# IVA_PRM register map
Vendor: Texas Instruments
Peripheral module from a debugger description file (folder omap5430_ES2_PUBLIC).
Registers are 32-bit, access not given, reset 0xFF0E03 unless marked. A register's access mark holds for its fields unless they carry their own. Offsets are as the file gives them; lines under a group give offsets from that group; [hi:lo] are bit positions; {n}, {i} and the like mark numbered series; 'fields as' and 'values as' point back to an identical list; <NAME> marks a mode.

## IVA_PRM
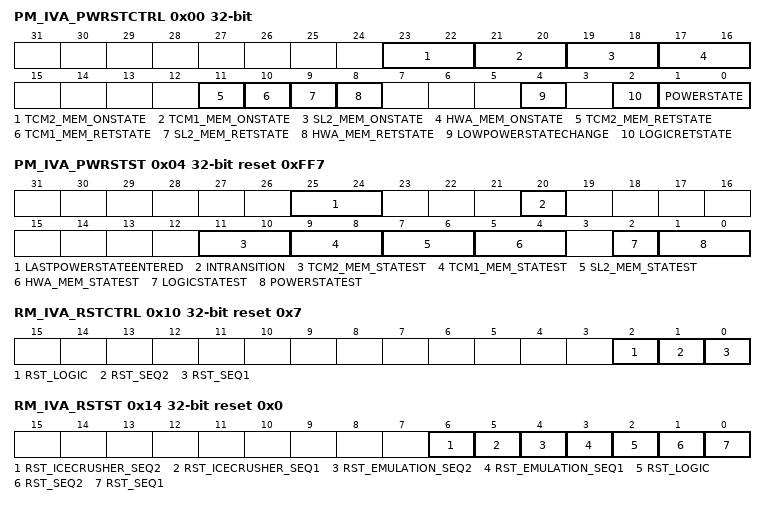
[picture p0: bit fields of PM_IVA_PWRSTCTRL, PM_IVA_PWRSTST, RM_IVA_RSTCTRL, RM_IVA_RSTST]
0x00 PM_IVA_PWRSTCTRL — This register controls the IVA power state to reach upon a domain sleep transition
  [23:22] TCM2_MEM_ONSTATE ro — TCM2 memory state when domain is ON.
    3=Mem_on (Memory bank is on when the domain is ON.)
  [21:20] TCM1_MEM_ONSTATE ro — TCM1 memory state when domain is ON.
    3=Mem_on (Memory bank is on when the domain is ON.)
  [19:18] SL2_MEM_ONSTATE ro — SL2 memory state when domain is ON.
    3=Mem_on (Memory bank is on when the domain is ON.)
  [17:16] HWA_MEM_ONSTATE ro — HWA memory state when domain is ON.
    3=Mem_on (Memory bank is on when the domain is ON.)
  [11] TCM2_MEM_RETSTATE rw — TCM2 memory state when domain is RETENTION.
    0=mem_off (Memory bank is off when the domain is in the RETENTION state.); 1=mem_ret (Memory bank is retained when domain is in RETENTION state.)
  [10] TCM1_MEM_RETSTATE rw — TCM1 memory state when domain is RETENTION.
    values as TCM2_MEM_RETSTATE
  [9] SL2_MEM_RETSTATE rw — SL2 memory state when domain is RETENTION.
    values as TCM2_MEM_RETSTATE
  [8] HWA_MEM_RETSTATE ro — HWA memory state when domain is RETENTION.
    0=mem_off (Memory bank is off when the domain is in the RETENTION state.)
  [4] LOWPOWERSTATECHANGE — Power state change request when domain has already performed a sleep transition. Allows going into deeper low power state without waking up the power domain. (access RW WSpecial)
    0=DIS (Do not request a low power state change.); 1=EN (Request a low power state change. This bit is automatically cleared when the power state is effectively changed or when power state is ON.)
  [2] LOGICRETSTATE ro — Logic state when power domain is RETENTION
    0=logic_off (Whole logic is off when the domain is in RETENTION state.)
  [1:0] POWERSTATE rw — Power state control
    0=OFF (Reserved); 1=RET (RETENTION state); 2=INACT (INACTIVE state); 3=ON (ON State)
0x04 PM_IVA_PWRSTST reset 0xFF7 — This register provides a status on the current IVA power domain state. [warm reset insensitive]
  [25:24] LASTPOWERSTATEENTERED — Last low power state entered. Set to 0x3 upon write of the same only. This register is intended for debug purpose only. (access RW W1toSet)
    3=ON (Power domain was previously ON-ACTIVE); 2=INACTIVE (Power domain was previously ON-INACTIVE); 1=RET (Power domain was previously in RETENTION); 0=OFF (Reserved)
  [20] INTRANSITION ro — Domain transition status
    0=No (No on-going transition on power domain); 1=Ongoing (Power domain transition is in progress.)
  [11:10] TCM2_MEM_STATEST ro — TCM2 memory state status
    0=Mem_off (Reserved); 1=Mem_ret (Memory is RETENTION); 3=Mem_on (Memory is ON)
  [9:8] TCM1_MEM_STATEST ro — TCM1 memory state status
    values as TCM2_MEM_STATEST
  [7:6] SL2_MEM_STATEST ro — SL2 memory state status
    values as TCM2_MEM_STATEST
  [5:4] HWA_MEM_STATEST ro — HWA memory state status
    values as TCM2_MEM_STATEST
  [2] LOGICSTATEST ro — Logic state status
    0=OFF (Logic in domain is OFF); 1=ON (Logic in domain is ON)
  [1:0] POWERSTATEST ro — Current power state status
    0=OFF (Reserved); 1=RET (Power domain is in RETENTION); 2=INACTIVE (Power domain is ON-INACTIVE); 3=ON (Power domain is ON-ACTIVE)
0x10 RM_IVA_RSTCTRL access per field reset 0x7 — This register controls the release of the IVA sub-system resets.
  [2] RST_LOGIC rw — IVA logic and SL2 reset control
    0=CLEAR (Reset is cleared for the IVA logic and SL2); 1=ASSERT (Reset is asserted for IVA logic and SL2)
  [1] RST_SEQ2 rw — IVA Sequencer2 reset control
    0=CLEAR (Reset is cleared for IVA Sequencer CPU2); 1=ASSERT (Reset is asserted for IVA Sequencer CPU2)
  [0] RST_SEQ1 rw — IVA sequencer1 reset control
    0=CLEAR (Reset is cleared for the IVA Sequencer CPU1); 1=ASSERT (Reset is asserted for the IVA sequencer CPU1)
0x14 RM_IVA_RSTST reset 0x0 — This register logs the different reset sources of the IVA domain. Each bit is set upon release of the domain reset signal. Must be cleared by software. [warm reset insensitive]
  [6] RST_ICECRUSHER_SEQ2 — Sequencer2 CPU has been reset due to IVA ICECRUSHER2 reset event (access RW W1toClr)
    0=RESET_NO (No icecrusher reset); 1=RESET_YES (Sequencer2 has been reset upon icecrusher reset)
  [5] RST_ICECRUSHER_SEQ1 — Sequencer1 CPU has been reset due to IVA ICECRUSHER1 reset event (access RW W1toClr)
    0=RESET_NO (No icecrusher reset); 1=RESET_YES (Sequencer1 has been reset upon icecrusher reset)
  [4] RST_EMULATION_SEQ2 — Sequencer2 CPU has been reset due to emulation reset source e.g. assert reset command initiated by the icepick module (access RW W1toClr)
    0=RESET_NO (No emulation reset); 1=RESET_YES (Sequencer2 has been reset upon emulation reset)
  [3] RST_EMULATION_SEQ1 — Sequencer1 CPU has been reset due to emulation reset source e.g. assert reset command initiated by the icepick module (access RW W1toClr)
    0=RESET_NO (No emulation reset); 1=RESET_YES (Sequencer1 has been reset upon emulation reset)
  [2] RST_LOGIC — IVA logic and SL2 SW reset (access RW W1toClr)
    0=RESET_NO (No SW reset occured); 1=RESET_YES (IVA logic and SL2 has been reset upon SW reset)
  [1] RST_SEQ2 — IVA Sequencer2 CPU SW reset (access RW W1toClr)
    0=RESET_NO (No SW reset occured); 1=RESET_YES (Sequencer2 has been reset upon SW reset)
  [0] RST_SEQ1 — IVA Sequencer1 CPU SW reset (access RW W1toClr)
    0=RESET_NO (No SW reset occured); 1=RESET_YES (Sequencer1 has been reset upon SW reset)
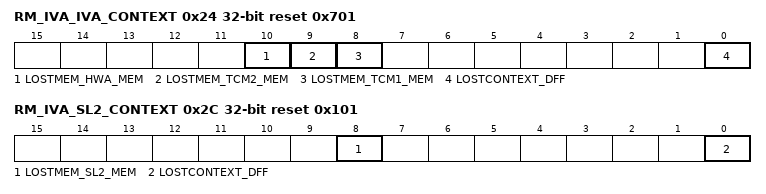
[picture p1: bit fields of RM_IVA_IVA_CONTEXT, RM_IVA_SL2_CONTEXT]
0x24 RM_IVA_IVA_CONTEXT reset 0x701 — This register contains dedicated IVA context statuses. [warm reset insensitive]
  [all] fields
    0=Maintained (Context has been maintained); 1=Lost (Context has been lost)
  [10] LOSTMEM_HWA_MEM — Specify if memory-based context in HWA_MEM memory bank has been lost due to a previous power transition or other reset source. (access RW W1toClr)
  [9] LOSTMEM_TCM2_MEM — Specify if memory-based context in TCM2_MEM memory bank has been lost due to a previous power transition or other reset source. (access RW W1toClr)
  [8] LOSTMEM_TCM1_MEM — Specify if memory-based context in TCM1_MEM memory bank has been lost due to a previous power transition or other reset source. (access RW W1toClr)
  [0] LOSTCONTEXT_DFF — Specify if DFF-based context has been lost due to a previous power transition or other reset source. (set upon assertion of IVA_RST signal) (access RW W1toClr)
0x2C RM_IVA_SL2_CONTEXT reset 0x101 — This register contains dedicated SL2 context statuses. [warm reset insensitive]
  [8] LOSTMEM_SL2_MEM — Specify if memory-based context in SL2_MEM memory bank has been lost due to a previous power transition or other reset source. (access RW W1toClr)
    values as the fields of RM_IVA_IVA_CONTEXT
  [0] LOSTCONTEXT_DFF — Specify if DFF-based context has been lost due to a previous power transition or other reset source. (set upon assertion of IVA_RST signal) (access RW W1toClr)
    values as the fields of RM_IVA_IVA_CONTEXT
